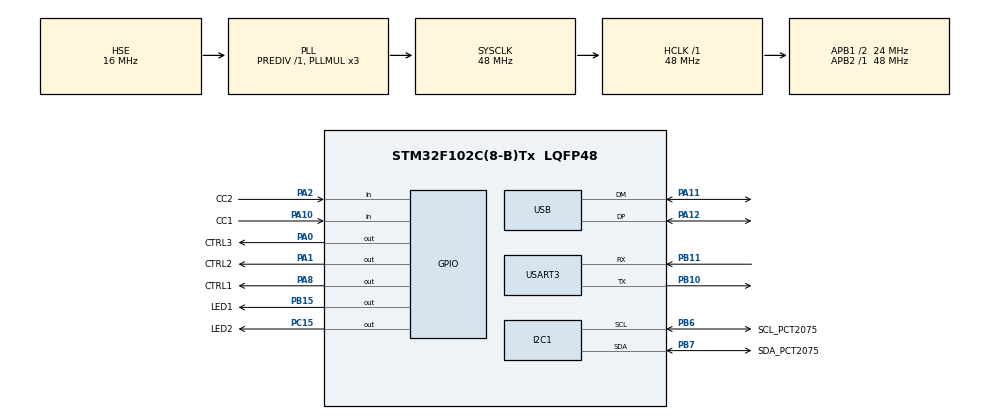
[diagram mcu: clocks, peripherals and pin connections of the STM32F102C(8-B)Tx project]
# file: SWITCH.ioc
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Mcu.Family=STM32F1
Mcu.Name=STM32F102C(8-B)Tx
Mcu.Package=LQFP48
NVIC.PriorityGroup=NVIC_PRIORITYGROUP_4
NVIC.TIM2_IRQn=true\:0\:0\:false\:false\:true\:true\:true\:true
NVIC.USB_LP_IRQn=true\:0\:0\:false\:false\:true\:true\:true\:true
PA0-WKUP.GPIO_Label=CTRL3
PA0-WKUP.Signal=GPIO_Output
PA1.GPIO_Label=CTRL2
PA1.Signal=GPIO_Output
PA10.GPIO_Label=CC1
PA10.Signal=GPIO_Input
PA11.Mode=Device
PA11.Signal=USB_DM
PA12.Mode=Device
PA12.Signal=USB_DP
PA13.Mode=Serial_Wire
PA13.Signal=SYS_JTMS-SWDIO
PA14.Mode=Serial_Wire
PA14.Signal=SYS_JTCK-SWCLK
PA2.GPIO_Label=CC2
PA2.Signal=GPIO_Input
PA8.GPIO_Label=CTRL1
PA8.Signal=GPIO_Output
PB10.Mode=Asynchronous
PB10.Signal=USART3_TX
PB11.Mode=Asynchronous
PB11.Signal=USART3_RX
PB15.GPIO_Label=LED1
PB15.Signal=GPIO_Output
PB6.GPIO_Label=SCL_PCT2075
PB6.Mode=I2C
PB6.Signal=I2C1_SCL
PB7.GPIO_Label=SDA_PCT2075
PB7.Mode=I2C
PB7.Signal=I2C1_SDA
PC15-OSC32_OUT.GPIO_Label=LED2
PC15-OSC32_OUT.Signal=GPIO_Output
PD0-OSC_IN.Mode=HSE-External-Oscillator
PD0-OSC_IN.Signal=RCC_OSC_IN
PD1-OSC_OUT.Mode=HSE-External-Oscillator
PD1-OSC_OUT.Signal=RCC_OSC_OUT
ProjectManager.HeapSize=0x200
ProjectManager.StackSize=0x400
ProjectManager.TargetToolchain=STM32CubeIDE
RCC.AHBFreq_Value=48000000
RCC.APB1CLKDivider=RCC_HCLK_DIV2
RCC.APB1Freq_Value=24000000
RCC.APB1TimFreq_Value=48000000
RCC.APB2Freq_Value=48000000
RCC.HCLKFreq_Value=48000000
RCC.HSE_VALUE=16000000
RCC.PLLMUL=RCC_PLL_MUL3
RCC.SYSCLKFreq_VALUE=48000000
RCC.SYSCLKSource=RCC_SYSCLKSOURCE_PLLCLK
RCC.USBFreq_Value=48000000
TIM2.Period=2000
TIM2.Prescaler=47999
USART3.VirtualMode=VM_ASYNC
USB.ep0_mps=DEP0CTL_MPS_64
USB_DEVICE.CLASS_NAME_FS=CDC
USB_DEVICE.USBD_SELF_POWERED=0
USB_DEVICE.VirtualMode=Cdc
USB_DEVICE.VirtualModeFS=Cdc_FS
VP_TIM2_VS_ClockSourceINT.Mode=Internal
VP_USB_DEVICE_VS_USB_DEVICE_CDC_FS.Mode=CDC_FS
board=PE1220_USB_USBTMC_Device

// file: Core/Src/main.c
/* USER CODE BEGIN Header */
/**
  ******************************************************************************
  * @file           : main.c
  * @brief          : Main program body
  ******************************************************************************
  * @attention
  *
  * Copyright (c) 2024 STMicroelectronics.
  * All rights reserved.
  *
  * This software is licensed under terms that can be found in the LICENSE file
  * in the root directory of this software component.
  * If no LICENSE file comes with this software, it is provided AS-IS.
  *
  ******************************************************************************
  */
/* USER CODE END Header */
#include "main.h"
#include "i2c.h"
#include "tim.h"
#include "usart.h"
#include "usb_device.h"
#include "gpio.h"

/* USER CODE BEGIN Includes */
#include "AddClass.h"
#include "usbd_desc.h"
#include "usbd_ctlreq.h"
#include "user_usbtmc_if.h"
#include "usbd_tmc.h"

/* USER CODE END Includes */

void SystemClock_Config(void);

int main(void)
{

  /* MCU Configuration--------------------------------------------------------*/

  /* Reset of all peripherals, Initializes the Flash interface and the Systick. */
  HAL_Init();

  /* Configure the system clock */
  SystemClock_Config();

  /* Initialize all configured peripherals */
  MX_GPIO_Init();
  MX_USB_DEVICE_Init();
  MX_TIM2_Init();
  MX_I2C1_Init();
  MX_USART3_UART_Init();
  /* USER CODE BEGIN 2 */
  USBTMC_SCPI_Command_Class_Add();
  /* USER CODE END 2 */

  /* Infinite loop */
  while (1)
  {

    /* USER CODE BEGIN 3 */
	  USBTMC_IncomingActionStart();

  }
  /* USER CODE END 3 */
}

void SystemClock_Config(void)
{
  RCC_OscInitTypeDef RCC_OscInitStruct = {0};
  RCC_ClkInitTypeDef RCC_ClkInitStruct = {0};
  RCC_PeriphCLKInitTypeDef PeriphClkInit = {0};

  /** Initializes the RCC Oscillators according to the specified parameters
  * in the RCC_OscInitTypeDef structure.
  */
  RCC_OscInitStruct.OscillatorType = RCC_OSCILLATORTYPE_HSE;
  RCC_OscInitStruct.HSEState = RCC_HSE_ON;
  RCC_OscInitStruct.HSEPredivValue = RCC_HSE_PREDIV_DIV1;
  RCC_OscInitStruct.HSIState = RCC_HSI_ON;
  RCC_OscInitStruct.PLL.PLLState = RCC_PLL_ON;
  RCC_OscInitStruct.PLL.PLLSource = RCC_PLLSOURCE_HSE;
  RCC_OscInitStruct.PLL.PLLMUL = RCC_PLL_MUL3;
  if (HAL_RCC_OscConfig(&RCC_OscInitStruct) != HAL_OK)
  {
    Error_Handler();
  }

  /** Initializes the CPU, AHB and APB buses clocks
  */
  RCC_ClkInitStruct.ClockType = RCC_CLOCKTYPE_HCLK|RCC_CLOCKTYPE_SYSCLK
                              |RCC_CLOCKTYPE_PCLK1|RCC_CLOCKTYPE_PCLK2;
  RCC_ClkInitStruct.SYSCLKSource = RCC_SYSCLKSOURCE_PLLCLK;
  RCC_ClkInitStruct.AHBCLKDivider = RCC_SYSCLK_DIV1;
  RCC_ClkInitStruct.APB1CLKDivider = RCC_HCLK_DIV2;
  RCC_ClkInitStruct.APB2CLKDivider = RCC_HCLK_DIV1;

  if (HAL_RCC_ClockConfig(&RCC_ClkInitStruct, FLASH_LATENCY_1) != HAL_OK)
  {
    Error_Handler();
  }
  PeriphClkInit.PeriphClockSelection = RCC_PERIPHCLK_USB;
  PeriphClkInit.UsbClockSelection = RCC_USBCLKSOURCE_PLL;
  if (HAL_RCCEx_PeriphCLKConfig(&PeriphClkInit) != HAL_OK)
  {
    Error_Handler();
  }
}

void Error_Handler(void)
{
  __disable_irq();
  while (1)
  {
  }
}
